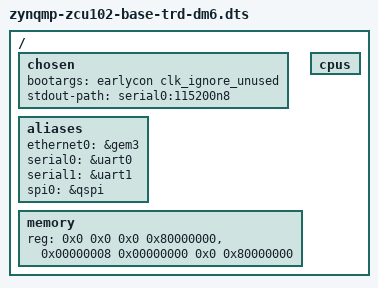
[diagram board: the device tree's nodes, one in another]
/*
 * CAUTION: This file is automatically generated by Xilinx.
 * Version:  
 * Today is: Mon Apr  3 17:39:27 2017
*/


/dts-v1/;
#include "zynqmp.dtsi"
#include "zynqmp-clk-ccf.dtsi"
#include "trd/zcu102-revb.dtsi"
#include "trd/pcw.dtsi"
/ {
	chosen {
		bootargs = "earlycon clk_ignore_unused";
		stdout-path = "serial0:115200n8";
	};
	aliases {
		ethernet0 = &gem3;
		serial0 = &uart0;
		serial1 = &uart1;
		spi0 = &qspi;
	};
	memory {
		device_type = "memory";
		reg = <0x0 0x0 0x0 0x80000000>, <0x00000008 0x00000000 0x0 0x80000000>;
	};
	cpus {
	};
};
#include "trd/zcu102-base-dm6.dtsi"
